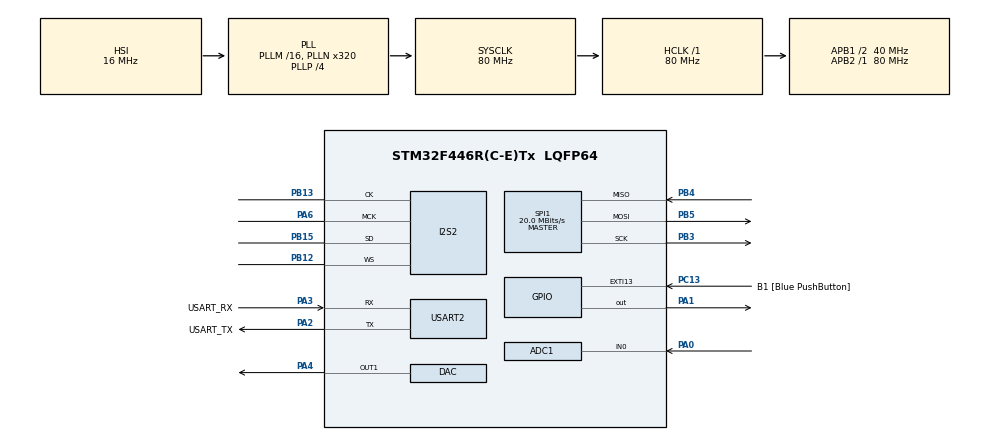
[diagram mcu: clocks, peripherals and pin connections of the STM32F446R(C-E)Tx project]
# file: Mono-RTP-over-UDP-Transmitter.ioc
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ADC1.Channel-0\#ChannelRegularConversion=ADC_CHANNEL_0
ADC1.NbrOfConversionFlag=1
ADC1.Rank-0\#ChannelRegularConversion=1
ADC1.SamplingTime-0\#ChannelRegularConversion=ADC_SAMPLETIME_3CYCLES
ADC1.master=1
DAC.DAC_Trigger=DAC_TRIGGER_T2_TRGO
Dma.DAC1.0.Direction=DMA_MEMORY_TO_PERIPH
Dma.DAC1.0.FIFOMode=DMA_FIFOMODE_DISABLE
Dma.DAC1.0.Instance=DMA1_Stream5
Dma.DAC1.0.MemDataAlignment=DMA_MDATAALIGN_WORD
Dma.DAC1.0.MemInc=DMA_MINC_ENABLE
Dma.DAC1.0.Mode=DMA_CIRCULAR
Dma.DAC1.0.PeriphDataAlignment=DMA_PDATAALIGN_WORD
Dma.DAC1.0.PeriphInc=DMA_PINC_DISABLE
Dma.DAC1.0.Priority=DMA_PRIORITY_HIGH
Dma.Request0=DAC1
Dma.Request1=SPI2_RX
Dma.SPI2_RX.1.Direction=DMA_PERIPH_TO_MEMORY
Dma.SPI2_RX.1.FIFOMode=DMA_FIFOMODE_DISABLE
Dma.SPI2_RX.1.Instance=DMA1_Stream3
Dma.SPI2_RX.1.MemDataAlignment=DMA_MDATAALIGN_HALFWORD
Dma.SPI2_RX.1.MemInc=DMA_MINC_ENABLE
Dma.SPI2_RX.1.Mode=DMA_CIRCULAR
Dma.SPI2_RX.1.PeriphDataAlignment=DMA_PDATAALIGN_HALFWORD
Dma.SPI2_RX.1.PeriphInc=DMA_PINC_DISABLE
Dma.SPI2_RX.1.Priority=DMA_PRIORITY_VERY_HIGH
I2S2.AudioFreq=I2S_AUDIOFREQ_48K
I2S2.DataFormat=I2S_DATAFORMAT_24B
I2S2.ErrorAudioFreq=0.0 %
I2S2.FullDuplexMode=I2S_FULLDUPLEXMODE_DISABLE
I2S2.Instance=SPI$Index
I2S2.Mode=I2S_MODE_MASTER_RX
I2S2.RealAudioFreq=48.0 KHz
I2S2.VirtualMode=I2S_MODE_MASTER
Mcu.Family=STM32F4
Mcu.Name=STM32F446R(C-E)Tx
Mcu.Package=LQFP64
NVIC.DMA1_Stream3_IRQn=true\:0\:0\:false\:false\:true\:false\:true\:true
NVIC.DMA1_Stream5_IRQn=true\:0\:0\:false\:false\:true\:false\:true\:true
NVIC.PriorityGroup=NVIC_PRIORITYGROUP_0
PA0-WKUP.Signal=ADCx_IN0
PA1.PinState=GPIO_PIN_SET
PA1.Signal=GPIO_Output
PA13.GPIO_Label=TMS
PA13.Mode=Serial_Wire
PA13.Signal=SYS_JTMS-SWDIO
PA14.GPIO_Label=TCK
PA14.Mode=Serial_Wire
PA14.Signal=SYS_JTCK-SWCLK
PA2.GPIO_Label=USART_TX
PA2.Mode=Asynchronous
PA2.Signal=USART2_TX
PA3.GPIO_Label=USART_RX
PA3.Mode=Asynchronous
PA3.Signal=USART2_RX
PA4.Signal=COMP_DAC1_group
PA6.GPIO_Speed=GPIO_SPEED_FREQ_VERY_HIGH
PA6.Mode=Master_Clock_Activated
PA6.Signal=I2S2_MCK
PB12.GPIO_Speed=GPIO_SPEED_FREQ_VERY_HIGH
PB12.Mode=Half_Duplex_Master
PB12.Signal=I2S2_WS
PB13.GPIO_Speed=GPIO_SPEED_FREQ_VERY_HIGH
PB13.Mode=Half_Duplex_Master
PB13.Signal=I2S2_CK
PB15.GPIO_Speed=GPIO_SPEED_FREQ_VERY_HIGH
PB15.Mode=Half_Duplex_Master
PB15.Signal=I2S2_SD
PB3.Mode=Full_Duplex_Master
PB3.Signal=SPI1_SCK
PB4.Mode=Full_Duplex_Master
PB4.Signal=SPI1_MISO
PB5.Mode=Full_Duplex_Master
PB5.Signal=SPI1_MOSI
PC13.GPIO_Label=B1 [Blue PushButton]
PC13.GPIO_ModeDefaultEXTI=GPIO_MODE_IT_FALLING
PC13.Signal=GPXTI13
PC14-OSC32_IN.Mode=LSE-External-Oscillator
PC14-OSC32_IN.Signal=RCC_OSC32_IN
PC15-OSC32_OUT.Mode=LSE-External-Oscillator
PC15-OSC32_OUT.Signal=RCC_OSC32_OUT
PH0-OSC_IN.Mode=HSE-External-Oscillator
PH0-OSC_IN.Signal=RCC_OSC_IN
PH1-OSC_OUT.Mode=HSE-External-Oscillator
PH1-OSC_OUT.Signal=RCC_OSC_OUT
ProjectManager.HeapSize=0x200
ProjectManager.StackSize=0x400
ProjectManager.TargetToolchain=STM32CubeIDE
RCC.48MHZClocksFreq_Value=84000000
RCC.AHBFreq_Value=80000000
RCC.APB1CLKDivider=RCC_HCLK_DIV2
RCC.APB1Freq_Value=40000000
RCC.APB1TimFreq_Value=80000000
RCC.APB2Freq_Value=80000000
RCC.APB2TimFreq_Value=80000000
RCC.CortexFreq_Value=80000000
RCC.FLatency-AdvancedSettings=FLASH_LATENCY_2
RCC.HCLKFreq_Value=80000000
RCC.HSE_VALUE=8000000
RCC.HSI_VALUE=16000000
RCC.PLLI2SM=10
RCC.PLLI2SR=5
RCC.PLLN=320
RCC.PLLP=RCC_PLLP_DIV4
RCC.SYSCLKFreq_VALUE=80000000
RCC.SYSCLKSource=RCC_SYSCLKSOURCE_PLLCLK
RCC.USBFreq_Value=160000000
RCC.VCOOutputFreq_Value=320000000
SH.ADCx_IN0.0=ADC1_IN0,IN0
SH.COMP_DAC1_group.0=DAC_OUT1,DAC_OUT1
SPI1.BaudRatePrescaler=SPI_BAUDRATEPRESCALER_4
SPI1.CalculateBaudRate=20.0 MBits/s
SPI1.Direction=SPI_DIRECTION_2LINES
SPI1.Mode=SPI_MODE_MASTER
SPI1.VirtualType=VM_MASTER
TIM2.Period=624
TIM2.TIM_MasterOutputTrigger=TIM_TRGO_UPDATE
USART2.VirtualMode=VM_ASYNC
VP_TIM2_VS_ClockSourceINT.Mode=Internal
board=NUCLEO-F446RE

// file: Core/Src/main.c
/* USER CODE BEGIN Header */
/**
  ******************************************************************************
  * @file           : main.c
  * @brief          : Main program body
  ******************************************************************************
  * @attention
  *
  * Copyright (c) 2026 STMicroelectronics.
  * All rights reserved.
  *
  * This software is licensed under terms that can be found in the LICENSE file
  * in the root directory of this software component.
  * If no LICENSE file comes with this software, it is provided AS-IS.
  *
  ******************************************************************************
  */

/* USER CODE END Header */
#include "main.h"

/* USER CODE BEGIN Includes */
#include "app.h"
/* USER CODE END Includes */

ADC_HandleTypeDef hadc1;

DAC_HandleTypeDef hdac;
DMA_HandleTypeDef hdma_dac1;

I2S_HandleTypeDef hi2s2;
DMA_HandleTypeDef hdma_spi2_rx;

SPI_HandleTypeDef hspi1;

TIM_HandleTypeDef htim2;

UART_HandleTypeDef huart2;

void SystemClock_Config(void);
static void MX_GPIO_Init(void);
static void MX_DMA_Init(void);
static void MX_USART2_UART_Init(void);
static void MX_DAC_Init(void);
static void MX_ADC1_Init(void);
static void MX_SPI1_Init(void);
static void MX_TIM2_Init(void);
static void MX_I2S2_Init(void);

int main(void)
{

  /* MCU Configuration--------------------------------------------------------*/

  /* Reset of all peripherals, Initializes the Flash interface and the Systick. */
  HAL_Init();

  /* Configure the system clock */
  SystemClock_Config();

  /* Initialize all configured peripherals */
  MX_GPIO_Init();
  MX_DMA_Init();
  MX_USART2_UART_Init();
  MX_DAC_Init();
  MX_ADC1_Init();
  MX_SPI1_Init();
  MX_TIM2_Init();
  MX_I2S2_Init();
  /* USER CODE BEGIN 2 */
  App_Init();
  /* USER CODE END 2 */

  /* Infinite loop */
  /* USER CODE BEGIN WHILE */
  while (1)
  {
    App_Run();

    /* USER CODE END WHILE */

  }
}

void SystemClock_Config(void)
{
  RCC_OscInitTypeDef RCC_OscInitStruct = {0};
  RCC_ClkInitTypeDef RCC_ClkInitStruct = {0};

  /** Configure the main internal regulator output voltage
  */
  __HAL_RCC_PWR_CLK_ENABLE();
  __HAL_PWR_VOLTAGESCALING_CONFIG(PWR_REGULATOR_VOLTAGE_SCALE3);

  /** Initializes the RCC Oscillators according to the specified parameters
  * in the RCC_OscInitTypeDef structure.
  */
  RCC_OscInitStruct.OscillatorType = RCC_OSCILLATORTYPE_HSI;
  RCC_OscInitStruct.HSIState = RCC_HSI_ON;
  RCC_OscInitStruct.HSICalibrationValue = RCC_HSICALIBRATION_DEFAULT;
  RCC_OscInitStruct.PLL.PLLState = RCC_PLL_ON;
  RCC_OscInitStruct.PLL.PLLSource = RCC_PLLSOURCE_HSI;
  RCC_OscInitStruct.PLL.PLLM = 16;
  RCC_OscInitStruct.PLL.PLLN = 320;
  RCC_OscInitStruct.PLL.PLLP = RCC_PLLP_DIV4;
  RCC_OscInitStruct.PLL.PLLQ = 2;
  RCC_OscInitStruct.PLL.PLLR = 2;
  if (HAL_RCC_OscConfig(&RCC_OscInitStruct) != HAL_OK)
  {
    Error_Handler();
  }

  /** Initializes the CPU, AHB and APB buses clocks
  */
  RCC_ClkInitStruct.ClockType = RCC_CLOCKTYPE_HCLK|RCC_CLOCKTYPE_SYSCLK
                              |RCC_CLOCKTYPE_PCLK1|RCC_CLOCKTYPE_PCLK2;
  RCC_ClkInitStruct.SYSCLKSource = RCC_SYSCLKSOURCE_PLLCLK;
  RCC_ClkInitStruct.AHBCLKDivider = RCC_SYSCLK_DIV1;
  RCC_ClkInitStruct.APB1CLKDivider = RCC_HCLK_DIV2;
  RCC_ClkInitStruct.APB2CLKDivider = RCC_HCLK_DIV1;

  if (HAL_RCC_ClockConfig(&RCC_ClkInitStruct, FLASH_LATENCY_2) != HAL_OK)
  {
    Error_Handler();
  }
}

static void MX_ADC1_Init(void)
{

  ADC_ChannelConfTypeDef sConfig = {0};

  /** Configure the global features of the ADC (Clock, Resolution, Data Alignment and number of conversion)
  */
  hadc1.Instance = ADC1;
  hadc1.Init.ClockPrescaler = ADC_CLOCK_SYNC_PCLK_DIV4;
  hadc1.Init.Resolution = ADC_RESOLUTION_12B;
  hadc1.Init.ScanConvMode = DISABLE;
  hadc1.Init.ContinuousConvMode = DISABLE;
  hadc1.Init.DiscontinuousConvMode = DISABLE;
  hadc1.Init.ExternalTrigConvEdge = ADC_EXTERNALTRIGCONVEDGE_NONE;
  hadc1.Init.ExternalTrigConv = ADC_SOFTWARE_START;
  hadc1.Init.DataAlign = ADC_DATAALIGN_RIGHT;
  hadc1.Init.NbrOfConversion = 1;
  hadc1.Init.DMAContinuousRequests = DISABLE;
  hadc1.Init.EOCSelection = ADC_EOC_SINGLE_CONV;
  if (HAL_ADC_Init(&hadc1) != HAL_OK)
  {
    Error_Handler();
  }

  /** Configure for the selected ADC regular channel its corresponding rank in the sequencer and its sample time.
  */
  sConfig.Channel = ADC_CHANNEL_0;
  sConfig.Rank = 1;
  sConfig.SamplingTime = ADC_SAMPLETIME_3CYCLES;
  if (HAL_ADC_ConfigChannel(&hadc1, &sConfig) != HAL_OK)
  {
    Error_Handler();
  }

}

static void MX_DAC_Init(void)
{

  DAC_ChannelConfTypeDef sConfig = {0};

  /** DAC Initialization
  */
  hdac.Instance = DAC;
  if (HAL_DAC_Init(&hdac) != HAL_OK)
  {
    Error_Handler();
  }

  /** DAC channel OUT1 config
  */
  sConfig.DAC_Trigger = DAC_TRIGGER_T2_TRGO;
  sConfig.DAC_OutputBuffer = DAC_OUTPUTBUFFER_ENABLE;
  if (HAL_DAC_ConfigChannel(&hdac, &sConfig, DAC_CHANNEL_1) != HAL_OK)
  {
    Error_Handler();
  }

}

static void MX_I2S2_Init(void)
{

  hi2s2.Instance = SPI2;
  hi2s2.Init.Mode = I2S_MODE_MASTER_RX;
  hi2s2.Init.Standard = I2S_STANDARD_PHILIPS;
  hi2s2.Init.DataFormat = I2S_DATAFORMAT_24B;
  hi2s2.Init.MCLKOutput = I2S_MCLKOUTPUT_ENABLE;
  hi2s2.Init.AudioFreq = I2S_AUDIOFREQ_48K;
  hi2s2.Init.CPOL = I2S_CPOL_LOW;
  hi2s2.Init.ClockSource = I2S_CLOCK_PLL;
  hi2s2.Init.FullDuplexMode = I2S_FULLDUPLEXMODE_DISABLE;
  if (HAL_I2S_Init(&hi2s2) != HAL_OK)
  {
    Error_Handler();
  }

}

static void MX_SPI1_Init(void)
{

  /* SPI1 parameter configuration*/
  hspi1.Instance = SPI1;
  hspi1.Init.Mode = SPI_MODE_MASTER;
  hspi1.Init.Direction = SPI_DIRECTION_2LINES;
  hspi1.Init.DataSize = SPI_DATASIZE_8BIT;
  hspi1.Init.CLKPolarity = SPI_POLARITY_LOW;
  hspi1.Init.CLKPhase = SPI_PHASE_1EDGE;
  hspi1.Init.NSS = SPI_NSS_SOFT;
  hspi1.Init.BaudRatePrescaler = SPI_BAUDRATEPRESCALER_4;
  hspi1.Init.FirstBit = SPI_FIRSTBIT_MSB;
  hspi1.Init.TIMode = SPI_TIMODE_DISABLE;
  hspi1.Init.CRCCalculation = SPI_CRCCALCULATION_DISABLE;
  hspi1.Init.CRCPolynomial = 10;
  if (HAL_SPI_Init(&hspi1) != HAL_OK)
  {
    Error_Handler();
  }

}

static void MX_TIM2_Init(void)
{

  TIM_ClockConfigTypeDef sClockSourceConfig = {0};
  TIM_MasterConfigTypeDef sMasterConfig = {0};

  htim2.Instance = TIM2;
  htim2.Init.Prescaler = 0;
  htim2.Init.CounterMode = TIM_COUNTERMODE_UP;
  htim2.Init.Period = 624;
  htim2.Init.ClockDivision = TIM_CLOCKDIVISION_DIV1;
  htim2.Init.AutoReloadPreload = TIM_AUTORELOAD_PRELOAD_DISABLE;
  if (HAL_TIM_Base_Init(&htim2) != HAL_OK)
  {
    Error_Handler();
  }
  sClockSourceConfig.ClockSource = TIM_CLOCKSOURCE_INTERNAL;
  if (HAL_TIM_ConfigClockSource(&htim2, &sClockSourceConfig) != HAL_OK)
  {
    Error_Handler();
  }
  sMasterConfig.MasterOutputTrigger = TIM_TRGO_UPDATE;
  sMasterConfig.MasterSlaveMode = TIM_MASTERSLAVEMODE_DISABLE;
  if (HAL_TIMEx_MasterConfigSynchronization(&htim2, &sMasterConfig) != HAL_OK)
  {
    Error_Handler();
  }

}

static void MX_USART2_UART_Init(void)
{

  huart2.Instance = USART2;
  huart2.Init.BaudRate = 115200;
  huart2.Init.WordLength = UART_WORDLENGTH_8B;
  huart2.Init.StopBits = UART_STOPBITS_1;
  huart2.Init.Parity = UART_PARITY_NONE;
  huart2.Init.Mode = UART_MODE_TX_RX;
  huart2.Init.HwFlowCtl = UART_HWCONTROL_NONE;
  huart2.Init.OverSampling = UART_OVERSAMPLING_16;
  if (HAL_UART_Init(&huart2) != HAL_OK)
  {
    Error_Handler();
  }

}

static void MX_DMA_Init(void)
{

  /* DMA controller clock enable */
  __HAL_RCC_DMA1_CLK_ENABLE();

  /* DMA interrupt init */
  /* DMA1_Stream3_IRQn interrupt configuration */
  HAL_NVIC_SetPriority(DMA1_Stream3_IRQn, 0, 0);
  HAL_NVIC_EnableIRQ(DMA1_Stream3_IRQn);
  /* DMA1_Stream5_IRQn interrupt configuration */
  HAL_NVIC_SetPriority(DMA1_Stream5_IRQn, 0, 0);
  HAL_NVIC_EnableIRQ(DMA1_Stream5_IRQn);

}

static void MX_GPIO_Init(void)
{
  GPIO_InitTypeDef GPIO_InitStruct = {0};

  /* GPIO Ports Clock Enable */
  __HAL_RCC_GPIOC_CLK_ENABLE();
  __HAL_RCC_GPIOH_CLK_ENABLE();
  __HAL_RCC_GPIOA_CLK_ENABLE();
  __HAL_RCC_GPIOB_CLK_ENABLE();

  /*Configure GPIO pin Output Level */
  HAL_GPIO_WritePin(GPIOA, GPIO_PIN_1, GPIO_PIN_SET);

  /*Configure GPIO pin : B1_Pin */
  GPIO_InitStruct.Pin = B1_Pin;
  GPIO_InitStruct.Mode = GPIO_MODE_IT_FALLING;
  GPIO_InitStruct.Pull = GPIO_NOPULL;
  HAL_GPIO_Init(B1_GPIO_Port, &GPIO_InitStruct);

  /*Configure GPIO pin : PA1 */
  GPIO_InitStruct.Pin = GPIO_PIN_1;
  GPIO_InitStruct.Mode = GPIO_MODE_OUTPUT_PP;
  GPIO_InitStruct.Pull = GPIO_NOPULL;
  GPIO_InitStruct.Speed = GPIO_SPEED_FREQ_LOW;
  HAL_GPIO_Init(GPIOA, &GPIO_InitStruct);

}

void Error_Handler(void)
{
  /* USER CODE BEGIN Error_Handler_Debug */
  /* User can add his own implementation to report the HAL error return state */
  __disable_irq();
  while (1)
  {
    App_Run();
  }
  /* USER CODE END Error_Handler_Debug */
}
